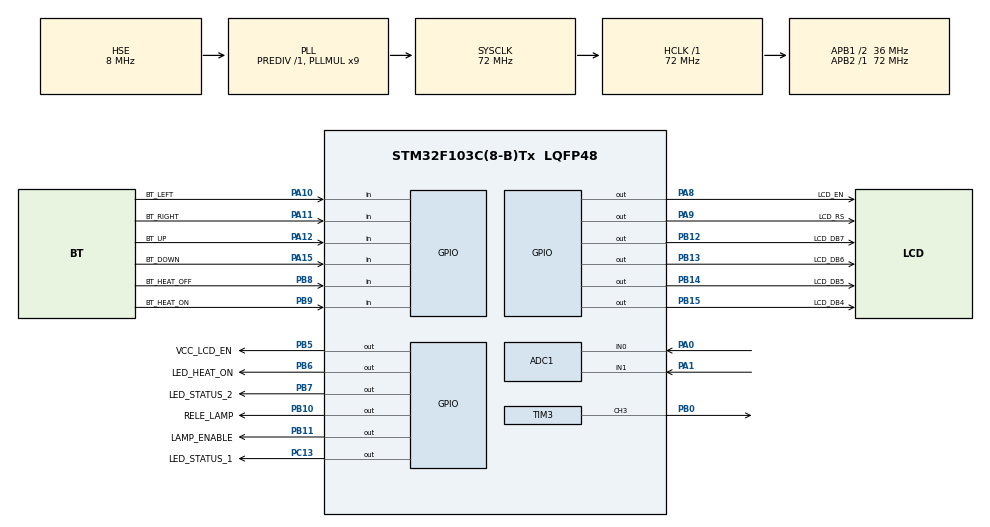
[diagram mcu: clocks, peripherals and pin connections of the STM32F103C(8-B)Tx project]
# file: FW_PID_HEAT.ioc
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ADC1.Channel-0\#ChannelRegularConversion=ADC_CHANNEL_0
ADC1.Channel-1\#ChannelRegularConversion=ADC_CHANNEL_1
ADC1.ContinuousConvMode=ENABLE
ADC1.NbrOfConversion=2
ADC1.NbrOfConversionFlag=1
ADC1.Rank-0\#ChannelRegularConversion=1
ADC1.Rank-1\#ChannelRegularConversion=2
ADC1.SamplingTime-0\#ChannelRegularConversion=ADC_SAMPLETIME_239CYCLES_5
ADC1.SamplingTime-1\#ChannelRegularConversion=ADC_SAMPLETIME_239CYCLES_5
ADC1.master=1
Dma.ADC1.0.Direction=DMA_PERIPH_TO_MEMORY
Dma.ADC1.0.Instance=DMA1_Channel1
Dma.ADC1.0.MemDataAlignment=DMA_MDATAALIGN_HALFWORD
Dma.ADC1.0.MemInc=DMA_MINC_ENABLE
Dma.ADC1.0.Mode=DMA_CIRCULAR
Dma.ADC1.0.PeriphDataAlignment=DMA_PDATAALIGN_HALFWORD
Dma.ADC1.0.PeriphInc=DMA_PINC_DISABLE
Dma.ADC1.0.Priority=DMA_PRIORITY_LOW
Dma.Request0=ADC1
Mcu.Family=STM32F1
Mcu.Name=STM32F103C(8-B)Tx
Mcu.Package=LQFP48
NVIC.ADC1_2_IRQn=true\:0\:0\:false\:false\:true\:true\:true\:true
NVIC.DMA1_Channel1_IRQn=true\:0\:0\:false\:false\:true\:false\:true\:true
NVIC.PriorityGroup=NVIC_PRIORITYGROUP_4
PA0-WKUP.Signal=ADCx_IN0
PA1.Signal=ADCx_IN1
PA10.GPIO_Label=BT_LEFT
PA10.Signal=GPIO_Input
PA11.GPIO_Label=BT_RIGHT
PA11.Signal=GPIO_Input
PA12.GPIO_Label=BT_UP
PA12.Signal=GPIO_Input
PA13.Mode=Serial_Wire
PA13.Signal=SYS_JTMS-SWDIO
PA14.Mode=Serial_Wire
PA14.Signal=SYS_JTCK-SWCLK
PA15.GPIO_Label=BT_DOWN
PA15.Signal=GPIO_Input
PA8.GPIO_Label=LCD_EN
PA8.Signal=GPIO_Output
PA9.GPIO_Label=LCD_RS
PA9.Signal=GPIO_Output
PB0.Signal=S_TIM3_CH3
PB10.GPIO_Label=RELE_LAMP
PB10.Signal=GPIO_Output
PB11.GPIO_Label=LAMP_ENABLE
PB11.Signal=GPIO_Output
PB12.GPIO_Label=LCD_DB7
PB12.Signal=GPIO_Output
PB13.GPIO_Label=LCD_DB6
PB13.Signal=GPIO_Output
PB14.GPIO_Label=LCD_DB5
PB14.Signal=GPIO_Output
PB15.GPIO_Label=LCD_DB4
PB15.Signal=GPIO_Output
PB5.GPIO_Label=VCC_LCD_EN
PB5.Signal=GPIO_Output
PB6.GPIO_Label=LED_HEAT_ON
PB6.Signal=GPIO_Output
PB7.GPIO_Label=LED_STATUS_2
PB7.Signal=GPIO_Output
PB8.GPIO_Label=BT_HEAT_OFF
PB8.Signal=GPIO_Input
PB9.GPIO_Label=BT_HEAT_ON
PB9.Signal=GPIO_Input
PC13-TAMPER-RTC.GPIO_Label=LED_STATUS_1
PC13-TAMPER-RTC.Signal=GPIO_Output
PC14-OSC32_IN.Mode=LSE-External-Oscillator
PC14-OSC32_IN.Signal=RCC_OSC32_IN
PC15-OSC32_OUT.Mode=LSE-External-Oscillator
PC15-OSC32_OUT.Signal=RCC_OSC32_OUT
PD0-OSC_IN.Mode=HSE-External-Oscillator
PD0-OSC_IN.Signal=RCC_OSC_IN
PD1-OSC_OUT.Mode=HSE-External-Oscillator
PD1-OSC_OUT.Signal=RCC_OSC_OUT
ProjectManager.HeapSize=0x200
ProjectManager.StackSize=0x400
ProjectManager.TargetToolchain=STM32CubeIDE
RCC.ADCPresc=RCC_ADCPCLK2_DIV6
RCC.AHBFreq_Value=72000000
RCC.APB1CLKDivider=RCC_HCLK_DIV2
RCC.APB1Freq_Value=36000000
RCC.APB1TimFreq_Value=72000000
RCC.APB2Freq_Value=72000000
RCC.APB2TimFreq_Value=72000000
RCC.HCLKFreq_Value=72000000
RCC.PLLMUL=RCC_PLL_MUL9
RCC.PLLSourceVirtual=RCC_PLLSOURCE_HSE
RCC.SYSCLKFreq_VALUE=72000000
RCC.SYSCLKSource=RCC_SYSCLKSOURCE_PLLCLK
RCC.USBFreq_Value=72000000
SH.ADCx_IN0.0=ADC1_IN0,IN0
SH.ADCx_IN1.0=ADC1_IN1,IN1
SH.S_TIM3_CH3.0=TIM3_CH3,PWM Generation3 CH3
TIM3.Channel-PWM\ Generation3\ CH3=TIM_CHANNEL_3
TIM3.OCFastMode_PWM-PWM\ Generation3\ CH3=TIM_OCFAST_ENABLE
TIM3.Period=999
TIM3.Prescaler=17
board=custom

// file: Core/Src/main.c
/* USER CODE BEGIN Header */
/**
  ******************************************************************************
  * @file           : main.c
  * @brief          : Main program body
  ******************************************************************************
  * @attention
  *
  * Copyright (c) 2025 STMicroelectronics.
  * All rights reserved.
  *
  * This software is licensed under terms that can be found in the LICENSE file
  * in the root directory of this software component.
  * If no LICENSE file comes with this software, it is provided AS-IS.
  *
  ******************************************************************************
  */
/* USER CODE END Header */
#include "main.h"

/* USER CODE BEGIN Includes */

#include "LCD_HD44780.h"
#include "sl.h"
#include "adc.h"
#include <stdio.h>

/* USER CODE END Includes */

/* USER CODE BEGIN PTD */

uint16_t adc_buffer[2] = {0};

/* USER CODE END PTD */

ADC_HandleTypeDef hadc1;
DMA_HandleTypeDef hdma_adc1;

TIM_HandleTypeDef htim3;

void SystemClock_Config(void);
static void MX_GPIO_Init(void);
static void MX_DMA_Init(void);
static void MX_ADC1_Init(void);
static void MX_TIM3_Init(void);

int main(void)
{

  /* MCU Configuration--------------------------------------------------------*/

  /* Reset of all peripherals, Initializes the Flash interface and the Systick. */
  HAL_Init();

  /* Configure the system clock */
  SystemClock_Config();

  /* Initialize all configured peripherals */
  MX_GPIO_Init();
  MX_DMA_Init();
  MX_ADC1_Init();
  MX_TIM3_Init();
  /* USER CODE BEGIN 2 */
  sl_init();
  vLCD_HD44780_Init();
  HAL_ADC_Start_DMA(&hadc1, (uint32_t*) adc_buffer, 2);
  HAL_TIM_PWM_Start(&htim3, TIM_CHANNEL_3);
  /* USER CODE END 2 */

  /* Infinite loop */
  while (1)
  {

    /* USER CODE BEGIN 3 */
    sl_update();
  }
  /* USER CODE END 3 */
}

void SystemClock_Config(void)
{
  RCC_OscInitTypeDef RCC_OscInitStruct = {0};
  RCC_ClkInitTypeDef RCC_ClkInitStruct = {0};
  RCC_PeriphCLKInitTypeDef PeriphClkInit = {0};

  /** Initializes the RCC Oscillators according to the specified parameters
  * in the RCC_OscInitTypeDef structure.
  */
  RCC_OscInitStruct.OscillatorType = RCC_OSCILLATORTYPE_HSE;
  RCC_OscInitStruct.HSEState = RCC_HSE_ON;
  RCC_OscInitStruct.HSEPredivValue = RCC_HSE_PREDIV_DIV1;
  RCC_OscInitStruct.HSIState = RCC_HSI_ON;
  RCC_OscInitStruct.PLL.PLLState = RCC_PLL_ON;
  RCC_OscInitStruct.PLL.PLLSource = RCC_PLLSOURCE_HSE;
  RCC_OscInitStruct.PLL.PLLMUL = RCC_PLL_MUL9;
  if (HAL_RCC_OscConfig(&RCC_OscInitStruct) != HAL_OK)
  {
    Error_Handler();
  }

  /** Initializes the CPU, AHB and APB buses clocks
  */
  RCC_ClkInitStruct.ClockType = RCC_CLOCKTYPE_HCLK|RCC_CLOCKTYPE_SYSCLK
                              |RCC_CLOCKTYPE_PCLK1|RCC_CLOCKTYPE_PCLK2;
  RCC_ClkInitStruct.SYSCLKSource = RCC_SYSCLKSOURCE_PLLCLK;
  RCC_ClkInitStruct.AHBCLKDivider = RCC_SYSCLK_DIV1;
  RCC_ClkInitStruct.APB1CLKDivider = RCC_HCLK_DIV2;
  RCC_ClkInitStruct.APB2CLKDivider = RCC_HCLK_DIV1;

  if (HAL_RCC_ClockConfig(&RCC_ClkInitStruct, FLASH_LATENCY_2) != HAL_OK)
  {
    Error_Handler();
  }
  PeriphClkInit.PeriphClockSelection = RCC_PERIPHCLK_ADC;
  PeriphClkInit.AdcClockSelection = RCC_ADCPCLK2_DIV6;
  if (HAL_RCCEx_PeriphCLKConfig(&PeriphClkInit) != HAL_OK)
  {
    Error_Handler();
  }
}

static void MX_ADC1_Init(void)
{

  ADC_ChannelConfTypeDef sConfig = {0};

  /** Common config
  */
  hadc1.Instance = ADC1;
  hadc1.Init.ScanConvMode = ADC_SCAN_ENABLE;
  hadc1.Init.ContinuousConvMode = ENABLE;
  hadc1.Init.DiscontinuousConvMode = DISABLE;
  hadc1.Init.ExternalTrigConv = ADC_SOFTWARE_START;
  hadc1.Init.DataAlign = ADC_DATAALIGN_RIGHT;
  hadc1.Init.NbrOfConversion = 2;
  if (HAL_ADC_Init(&hadc1) != HAL_OK)
  {
    Error_Handler();
  }

  /** Configure Regular Channel
  */
  sConfig.Channel = ADC_CHANNEL_0;
  sConfig.Rank = ADC_REGULAR_RANK_1;
  sConfig.SamplingTime = ADC_SAMPLETIME_239CYCLES_5;
  if (HAL_ADC_ConfigChannel(&hadc1, &sConfig) != HAL_OK)
  {
    Error_Handler();
  }

  /** Configure Regular Channel
  */
  sConfig.Channel = ADC_CHANNEL_1;
  sConfig.Rank = ADC_REGULAR_RANK_2;
  if (HAL_ADC_ConfigChannel(&hadc1, &sConfig) != HAL_OK)
  {
    Error_Handler();
  }

}

static void MX_TIM3_Init(void)
{

  TIM_MasterConfigTypeDef sMasterConfig = {0};
  TIM_OC_InitTypeDef sConfigOC = {0};

  htim3.Instance = TIM3;
  htim3.Init.Prescaler = 17;
  htim3.Init.CounterMode = TIM_COUNTERMODE_UP;
  htim3.Init.Period = 999;
  htim3.Init.ClockDivision = TIM_CLOCKDIVISION_DIV1;
  htim3.Init.AutoReloadPreload = TIM_AUTORELOAD_PRELOAD_DISABLE;
  if (HAL_TIM_PWM_Init(&htim3) != HAL_OK)
  {
    Error_Handler();
  }
  sMasterConfig.MasterOutputTrigger = TIM_TRGO_RESET;
  sMasterConfig.MasterSlaveMode = TIM_MASTERSLAVEMODE_DISABLE;
  if (HAL_TIMEx_MasterConfigSynchronization(&htim3, &sMasterConfig) != HAL_OK)
  {
    Error_Handler();
  }
  sConfigOC.OCMode = TIM_OCMODE_PWM1;
  sConfigOC.Pulse = 0;
  sConfigOC.OCPolarity = TIM_OCPOLARITY_HIGH;
  sConfigOC.OCFastMode = TIM_OCFAST_ENABLE;
  if (HAL_TIM_PWM_ConfigChannel(&htim3, &sConfigOC, TIM_CHANNEL_3) != HAL_OK)
  {
    Error_Handler();
  }
  HAL_TIM_MspPostInit(&htim3);

}

static void MX_DMA_Init(void)
{

  /* DMA controller clock enable */
  __HAL_RCC_DMA1_CLK_ENABLE();

  /* DMA interrupt init */
  /* DMA1_Channel1_IRQn interrupt configuration */
  HAL_NVIC_SetPriority(DMA1_Channel1_IRQn, 0, 0);
  HAL_NVIC_EnableIRQ(DMA1_Channel1_IRQn);

}

static void MX_GPIO_Init(void)
{
  GPIO_InitTypeDef GPIO_InitStruct = {0};

  /* GPIO Ports Clock Enable */
  __HAL_RCC_GPIOC_CLK_ENABLE();
  __HAL_RCC_GPIOD_CLK_ENABLE();
  __HAL_RCC_GPIOA_CLK_ENABLE();
  __HAL_RCC_GPIOB_CLK_ENABLE();

  /*Configure GPIO pin Output Level */
  HAL_GPIO_WritePin(LED_STATUS_1_GPIO_Port, LED_STATUS_1_Pin, GPIO_PIN_RESET);

  /*Configure GPIO pin Output Level */
  HAL_GPIO_WritePin(GPIOB, RELE_LAMP_Pin|LAMP_ENABLE_Pin|LCD_DB7_Pin|LCD_DB6_Pin
                          |LCD_DB5_Pin|LCD_DB4_Pin|VCC_LCD_EN_Pin|LED_HEAT_ON_Pin
                          |LED_STATUS_2_Pin, GPIO_PIN_RESET);

  /*Configure GPIO pin Output Level */
  HAL_GPIO_WritePin(GPIOA, LCD_EN_Pin|LCD_RS_Pin, GPIO_PIN_RESET);

  /*Configure GPIO pin : LED_STATUS_1_Pin */
  GPIO_InitStruct.Pin = LED_STATUS_1_Pin;
  GPIO_InitStruct.Mode = GPIO_MODE_OUTPUT_PP;
  GPIO_InitStruct.Pull = GPIO_NOPULL;
  GPIO_InitStruct.Speed = GPIO_SPEED_FREQ_LOW;
  HAL_GPIO_Init(LED_STATUS_1_GPIO_Port, &GPIO_InitStruct);

  /*Configure GPIO pins : RELE_LAMP_Pin LAMP_ENABLE_Pin LCD_DB7_Pin LCD_DB6_Pin
                           LCD_DB5_Pin LCD_DB4_Pin VCC_LCD_EN_Pin LED_HEAT_ON_Pin
                           LED_STATUS_2_Pin */
  GPIO_InitStruct.Pin = RELE_LAMP_Pin|LAMP_ENABLE_Pin|LCD_DB7_Pin|LCD_DB6_Pin
                          |LCD_DB5_Pin|LCD_DB4_Pin|VCC_LCD_EN_Pin|LED_HEAT_ON_Pin
                          |LED_STATUS_2_Pin;
  GPIO_InitStruct.Mode = GPIO_MODE_OUTPUT_PP;
  GPIO_InitStruct.Pull = GPIO_NOPULL;
  GPIO_InitStruct.Speed = GPIO_SPEED_FREQ_LOW;
  HAL_GPIO_Init(GPIOB, &GPIO_InitStruct);

  /*Configure GPIO pins : LCD_EN_Pin LCD_RS_Pin */
  GPIO_InitStruct.Pin = LCD_EN_Pin|LCD_RS_Pin;
  GPIO_InitStruct.Mode = GPIO_MODE_OUTPUT_PP;
  GPIO_InitStruct.Pull = GPIO_NOPULL;
  GPIO_InitStruct.Speed = GPIO_SPEED_FREQ_LOW;
  HAL_GPIO_Init(GPIOA, &GPIO_InitStruct);

  /*Configure GPIO pins : BT_LEFT_Pin BT_RIGHT_Pin BT_UP_Pin BT_DOWN_Pin */
  GPIO_InitStruct.Pin = BT_LEFT_Pin|BT_RIGHT_Pin|BT_UP_Pin|BT_DOWN_Pin;
  GPIO_InitStruct.Mode = GPIO_MODE_INPUT;
  GPIO_InitStruct.Pull = GPIO_NOPULL;
  HAL_GPIO_Init(GPIOA, &GPIO_InitStruct);

  /*Configure GPIO pins : BT_HEAT_OFF_Pin BT_HEAT_ON_Pin */
  GPIO_InitStruct.Pin = BT_HEAT_OFF_Pin|BT_HEAT_ON_Pin;
  GPIO_InitStruct.Mode = GPIO_MODE_INPUT;
  GPIO_InitStruct.Pull = GPIO_NOPULL;
  HAL_GPIO_Init(GPIOB, &GPIO_InitStruct);

}

void Error_Handler(void)
{
  __disable_irq();
  while (1)
  {
  }
}
